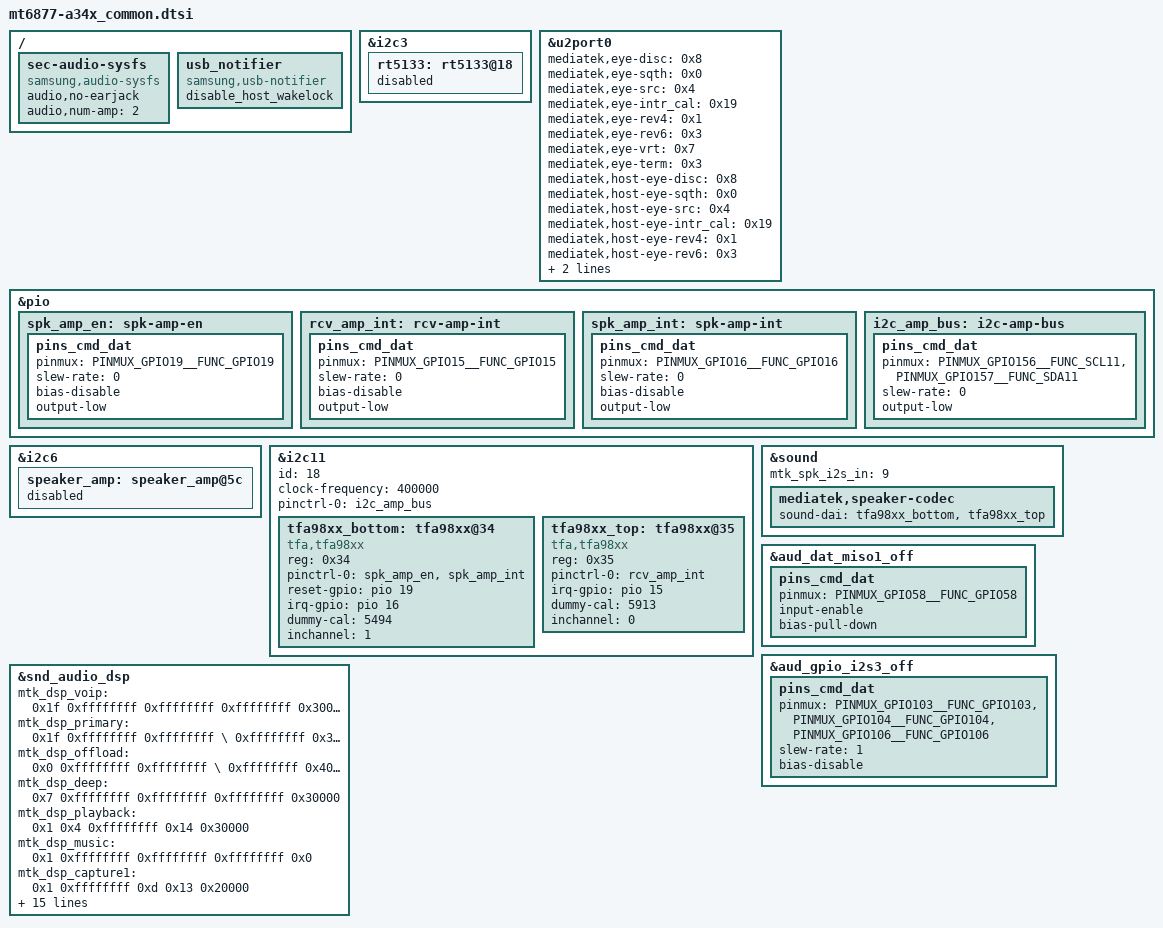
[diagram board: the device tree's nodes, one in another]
/* Generated by Samsung for MTK vendor board
 * If these files should be changed, then please make a sync with MTK
*/

/* Add Samsung configuration over here */
#include "display_lcd_a34x_common.dtsi"


&i2c3 {
	rt5133: rt5133@18 {
		status = "disabled";
	};
};


/* Add Samsung configuration over here */
/ {
	fragment@model {
		target-path = "/";
		__overlay__ {
			sec-audio-sysfs {
				compatible = "samsung,audio-sysfs";
				status = "okay";
				audio,no-earjack;
				audio,num-amp = <2>;
			};

			usb_notifier {
				compatible = "samsung,usb-notifier";
				disable_host_wakelock;
			};
		};
	};
};

&u2port0 {
	mediatek,eye-disc = <0x8>;
	mediatek,eye-sqth = <0x0>;
	mediatek,eye-src = <0x4>;
	mediatek,eye-intr_cal = <0x19>;
	mediatek,eye-rev4 = <0x1>;
	mediatek,eye-rev6 = <0x3>;
	mediatek,eye-vrt = <0x7>;
	mediatek,eye-term = <0x3>;
	mediatek,host-eye-disc = <0x8>;
	mediatek,host-eye-sqth = <0x0>;
	mediatek,host-eye-src = <0x4>;
	mediatek,host-eye-intr_cal = <0x19>;
	mediatek,host-eye-rev4 = <0x1>;
	mediatek,host-eye-rev6 = <0x3>;
	mediatek,host-eye-vrt = <0x7>;
	mediatek,host-eye-term = <0x3>;
};

&pio {
	spk_amp_en: spk-amp-en {
		pins_cmd_dat {
			pinmux = <PINMUX_GPIO19__FUNC_GPIO19>;
			slew-rate = <0>;
			bias-disable;
			output-low;
		};
	};

	rcv_amp_int: rcv-amp-int {
		pins_cmd_dat {
			pinmux = <PINMUX_GPIO15__FUNC_GPIO15>;
			slew-rate = <0>;
			bias-disable;
			output-low;
		};
	};

	spk_amp_int: spk-amp-int {
		pins_cmd_dat {
			pinmux = <PINMUX_GPIO16__FUNC_GPIO16>;
			slew-rate = <0>;
			bias-disable;
			output-low;
		};
	};

	i2c_amp_bus: i2c-amp-bus {
		pins_cmd_dat {
			pinmux = <PINMUX_GPIO156__FUNC_SCL11>,
				<PINMUX_GPIO157__FUNC_SDA11>;
			slew-rate = <0>;
			output-low;
		};
	};
};

&i2c6 {
	speaker_amp: speaker_amp@5c {
		status = "disabled";
	};
};

&i2c11 {
	status = "okay";
	id = <18>;
	clock-frequency = <400000>;
	#address-cells = <1>;
	#size-cells = <0>;

	pinctrl-names = "default";
	pinctrl-0 = <&i2c_amp_bus>;

	tfa98xx_bottom: tfa98xx@34 {
		#sound-dai-cells = <0>;
		compatible = "tfa,tfa98xx";
		reg = <0x34>;

		pinctrl-names = "default";
		pinctrl-0 = <&spk_amp_en &spk_amp_int>;

		reset-gpio = <&pio 19  0>;
		irq-gpio = <&pio 16 0>;

		dummy-cal = <5494>;
		inchannel = <1>; /*right*/
	};

	tfa98xx_top: tfa98xx@35 {
		#sound-dai-cells = <0>;
		compatible = "tfa,tfa98xx";
		reg = <0x35>;

		pinctrl-names = "default";
		pinctrl-0 = <&rcv_amp_int>;

		irq-gpio = <&pio 15 0>;

		dummy-cal = <5913>;
		inchannel = <0>; /*left*/
	};
};

&sound {
	mtk_spk_i2s_in = <9>;
	mediatek,speaker-codec {
		#sound-dai-cells = <2>;
		sound-dai = <&tfa98xx_bottom &tfa98xx_top>;
	};
};

&aud_dat_miso1_off {
	pins_cmd_dat {
		pinmux = <PINMUX_GPIO58__FUNC_GPIO58>;
		input-enable;
		bias-pull-down;
	};
};

&aud_gpio_i2s3_off {
	pins_cmd_dat {
		pinmux = <PINMUX_GPIO103__FUNC_GPIO103>,
			 <PINMUX_GPIO104__FUNC_GPIO104>,
			 <PINMUX_GPIO106__FUNC_GPIO106>;
		slew-rate = <1>;
		bias-disable;
	};
};

&snd_audio_dsp {
	mtk_dsp_voip = <0x1f 0xffffffff 0xffffffff 0xffffffff 0x30000>;
	mtk_dsp_primary = <0x1f 0xffffffff 0xffffffff \
				0xffffffff 0x30000>;
	mtk_dsp_offload = <0x0 0xffffffff 0xffffffff \
				0xffffffff 0x400000>;
	mtk_dsp_deep = <0x7 0xffffffff 0xffffffff 0xffffffff 0x30000>;
	mtk_dsp_playback = <0x1 0x4 0xffffffff 0x14 0x30000>;
	mtk_dsp_music = <0x1 0xffffffff 0xffffffff 0xffffffff 0x0>;
	mtk_dsp_capture1 = <0x1 0xffffffff 0xd 0x13 0x20000>;
	mtk_dsp_a2dp = <0x1 0xffffffff 0xffffffff 0xffffffff 0x40000>;
	mtk_dsp_dataprovider = <0x0 0xffffffff 0xf 0xffffffff 0x30000>;
	mtk_dsp_call_final = <0x5 0x4 0x10 0x14 0x18000>;
	mtk_dsp_fast = <0x5 0xffffffff 0xffffffff 0xffffffff 0x5000>;
	mtk_dsp_ktv = <0x1 0x8 0x12 0xffffffff 0x10000>;
	mtk_dsp_capture_raw = <0x0 0xffffffff 0xffffffff 0xffffffff 0x20000>;
	mtk_dsp_fm = <0x1 0xffffffff 0x10 0xffffffff 0x10000>;
	mtk_dsp_ver = <0x1>;
	swdsp_smartpa_process_enable = <0x5>;
	mtk_dsp_mem_afe = <0x1 0x40000>; /* always enable */
};
